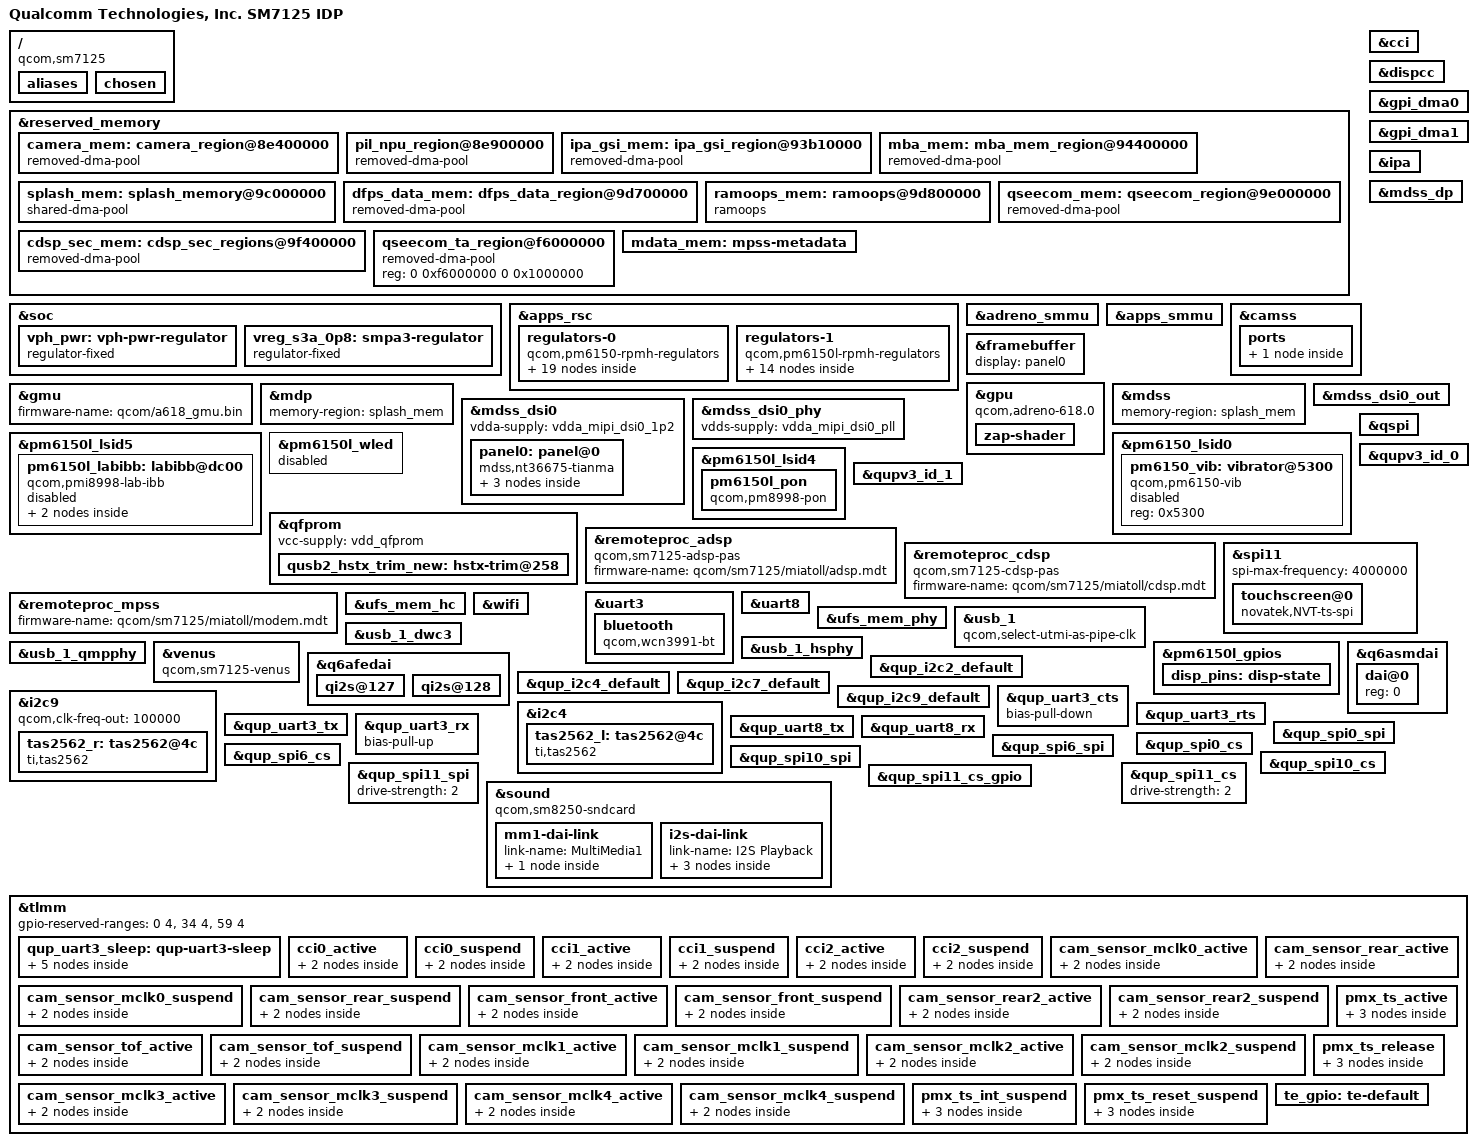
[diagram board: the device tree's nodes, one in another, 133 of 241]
// SPDX-License-Identifier: BSD-3-Clause
/*
 * SM7125 IDP board device tree source
 *
 * Copyright (c) 2019, The Linux Foundation. All rights reserved.
 * Copyright (c) 2023, 99degree <https://github.com/99degree/>
 *
 */

/dts-v1/;

#include <dt-bindings/arm/qcom,ids.h>
#include <dt-bindings/firmware/qcom,scm.h>
#include <dt-bindings/gpio/gpio.h>
#include <dt-bindings/regulator/qcom,rpmh-regulator.h>
#include <dt-bindings/pinctrl/qcom,pmic-gpio.h>
#include <dt-bindings/sound/qcom,q6asm.h>
#include "sm7125-xiaomi-common.dtsi"
#include "sm7125-idp.dtsi"
#include "pm6150.dtsi"
#include "pm6150l.dtsi"

/delete-node/ &cont_splash_mem;

/ {
	model = "Qualcomm Technologies, Inc. SM7125 IDP";
	compatible = "qcom,sm7125", "qcom,sc7180-idp", "qcom,sc7180";
	qcom,board-id = <0x50022 0x1>;
	qcom,msm-name = "ATOLL-AB";
	qcom,pmic-name = "PM6150";

	aliases {
		bluetooth0 = &bluetooth;
		hsuart0 = &uart3;
		serial0 = &uart8;
		wifi0 = &wifi;
		qupv3_se9_i2c = &i2c9;
		qupv3_se4_i2c = &i2c4;

	};

	chosen {
		#address-cells = <2>;
		#size-cells = <2>;
		ranges;

		//TODO: remove unneeded once all sorta out.
		bootargs = "pd_ignore_unused no_console_suspend kpti=off nokaslr ignore_loglevel clk_ignore_unused";

		stdout-path = "serial0:115200n8";
	};

};


/*
 * Reserved memory changes
 *
 * Delete all unused memory nodes and define the peripheral memory regions
 * required by the board dts.
 *
 */

&reserved_memory {
	
/*
[    0.000000] Memory limit set/overridden to 5068MB
[    0.000000] Reserved memory: created CMA memory pool at 0x00000000f7000000, size 140 MiB
[    0.000000] OF: reserved mem: initialized node secure_display_region, compatible id shared-dma-pool
[    0.000000] Reserved memory: created CMA memory pool at 0x00000000f6000000, size 16 MiB
[    0.000000] OF: reserved mem: initialized node qseecom_ta_region, compatible id shared-dma-pool
[    0.000000] Reserved memory: created CMA memory pool at 0x00000000f5800000, size 8 MiB
[    0.000000] OF: reserved mem: initialized node adsp_region, compatible id shared-dma-pool
[    0.000000] Reserved memory: created CMA memory pool at 0x00000000f3800000, size 32 MiB
[    0.000000] OF: reserved mem: initialized node linux,cma, compatible id shared-dma-pool

[    0.000000] Removed memory: created DMA memory pool at 0x0000000080000000, size 6 MiB
[    0.000000] OF: reserved mem: initialized node hyp_region@80000000, compatible id removed-dma-pool
[    0.000000] Removed memory: created DMA memory pool at 0x0000000080700000, size 1 MiB
[    0.000000] OF: reserved mem: initialized node xbl_aop_mem@80700000, compatible id removed-dma-pool
[    0.000000] Removed memory: created DMA memory pool at 0x00000000808ff000, size 0 MiB
[    0.000000] OF: reserved mem: initialized node sec_apps_region@808ff000, compatible id removed-dma-pool
[    0.000000] Removed memory: created DMA memory pool at 0x0000000080900000, size 2 MiB
[    0.000000] OF: reserved mem: initialized node smem@80900000, compatible id removed-dma-pool
[    0.000000] Removed memory: created DMA memory pool at 0x0000000080b00000, size 57 MiB
[    0.000000] OF: reserved mem: initialized node removed_region@80b00000, compatible id removed-dma-pool
[    0.000000] Removed memory: created DMA memory pool at 0x0000000086000000, size 132 MiB
[    0.000000] OF: reserved mem: initialized node modem_region@86000000, compatible id removed-dma-pool
[    0.000000] Removed memory: created DMA memory pool at 0x000000008e400000, size 5 MiB
[    0.000000] OF: reserved mem: initialized node camera_region@8e400000, compatible id removed-dma-pool
[    0.000000] Removed memory: created DMA memory pool at 0x000000008e900000, size 5 MiB
[    0.000000] OF: reserved mem: initialized node pil_npu_region@8e900000, compatible id removed-dma-pool
[    0.000000] Removed memory: created DMA memory pool at 0x000000008ee00000, size 5 MiB
[    0.000000] OF: reserved mem: initialized node pil_video_region@8ee00000, compatible id removed-dma-pool
[    0.000000] Removed memory: created DMA memory pool at 0x000000008f300000, size 30 MiB
[    0.000000] OF: reserved mem: initialized node cdsp_regions@8f300000, compatible id removed-dma-pool
[    0.000000] Removed memory: created DMA memory pool at 0x0000000091100000, size 40 MiB
[    0.000000] OF: reserved mem: initialized node pil_adsp_region@91100000, compatible id removed-dma-pool
[    0.000000] Removed memory: created DMA memory pool at 0x0000000093900000, size 2 MiB
[    0.000000] OF: reserved mem: initialized node wlan_fw_region@93900000, compatible id removed-dma-pool
[    0.000000] Removed memory: created DMA memory pool at 0x0000000093b00000, size 0 MiB
[    0.000000] OF: reserved mem: initialized node ipa_fw_region@93b00000, compatible id removed-dma-pool
[    0.000000] Removed memory: created DMA memory pool at 0x0000000093b10000, size 0 MiB
[    0.000000] OF: reserved mem: initialized node ipa_gsi_region@93b10000, compatible id removed-dma-pool
[    0.000000] Removed memory: created DMA memory pool at 0x0000000093b15000, size 0 MiB
[    0.000000] OF: reserved mem: initialized node gpu_region@93b15000, compatible id removed-dma-pool
[    0.000000] Reserved memory: created DMA memory pool at 0x000000009e000000, size 20 MiB
[    0.000000] OF: reserved mem: initialized node qseecom_region@9e000000, compatible id shared-dma-pool
[    0.000000] Removed memory: created DMA memory pool at 0x000000009f400000, size 30 MiB
[    0.000000] OF: reserved mem: initialized node cdsp_sec_regions@0x9f400000, compatible id removed-dma-pool
[    0.000000] cma: dma_contiguous_reserve(limit 100000000)
*/	

#if 0
		/* below node will get modified by bootloader, node name can't change. */
		kernel_mem: memory@80000000 {
			compatible = "removed-dma-pool";
			no-map;
			reg = <0x00 0x80000000 0x00 0x600000>;
		};
		
		memory@80600000 {
			compatible = "removed-dma-pool";
			no-map;
			reg = <0x00 0x80600000 0x00 0x200000>;
		};

		memory@808ff000 {
			compatible = "removed-dma-pool";
			no-map;
			reg = <0x00 0x808ff000 0x00 0x1000>;
		};

		smem: memory@80900000 {
			compatible = "removed-dma-pool";
			no-map;
			reg = <0x00 0x80900000 0x00 0x200000>;
		};

		atf_mem: memory@80b00000 {
			compatible = "removed-dma-pool";
			no-map;
			reg = <0x00 0x80b00000 0x00 0x3900000>;
		};
#endif
		camera_mem: camera_region@8e400000 {
			compatible = "removed-dma-pool";
			no-map;
			reg = <0x00 0x8e400000 0x00 0x500000>;
		};
		
		pil_npu_region@8e900000 {
			compatible = "removed-dma-pool";
			no-map;
			reg = <0x00 0x8e900000 0x00 0x500000>;
		};

		ipa_gsi_mem: ipa_gsi_region@93b10000 {
			compatible = "removed-dma-pool";
			no-map;
			reg = <0x00 0x93b10000 0x00 0x5000>;
		};

		mba_mem: mba_mem_region@94400000 {
			compatible = "removed-dma-pool";
			reg = <0x0 0x94400000 0x0 0x200000>;
			no-map;
		};

		splash_mem: splash_memory@9c000000 {
			compatible = "shared-dma-pool";
			reg = <0x0 0x9c000000 0x0 0x1700000>;
			no-map;
		};

		dfps_data_mem: dfps_data_region@9d700000 {
			reg = <0x00 0x9d700000 0x00 0x100000>;
			compatible = "removed-dma-pool";
			no-map;
		};
		
		ramoops_mem: ramoops@9d800000 {
			compatible = "ramoops", "removed-dma-pool";
			reg = <0x00 0x9d800000 0x00 0x600000>;
			console-size = <0x100000>;
			ftrace-size = <0x200000>;			
			ecc-size = <0x10>;
			pmsg-size = <0x200000>;
			record-size = <0x80000>;
		};

		qseecom_mem: qseecom_region@9e000000 {
			compatible = "removed-dma-pool";
			no-map;
			reg = <0x00 0x9e000000 0x00 0x1400000>;
		};
		
		cdsp_sec_mem: cdsp_sec_regions@9f400000 {
			compatible = "removed-dma-pool";
			no-map;
			reg = <0x00 0x9f400000 0x00 0x1e00000>;
		};

#if 0
		linux,cma@f3800000 {
			compatible = "shared-dma-pool";
			reg = <0 0xf3800000 0 0x2000000>;
		};
#endif
		qseecom_ta_region@f6000000 {
			compatible = "removed-dma-pool";
			reg = <0 0xf6000000 0 0x1000000>;
		};
		
#if 0
		secure_display_region@f7000000 {
			compatible = "shared-dma-pool";
			reg = <0 0xf7000000 0 0x8c00000>;
			
		};
#endif
		mdata_mem: mpss-metadata {
			alloc-ranges = <0x0 0xa0000000 0x0 0x20000000>;
			size = <0x0 0x4000>;
			no-map;
		};
};

&soc {
	vph_pwr: vph-pwr-regulator {
		compatible = "regulator-fixed";
		regulator-name = "vph_pwr";
		regulator-min-microvolt = <3700000>;
		regulator-max-microvolt = <3700000>;
	};

	// S3A is really mx.lvl but it's there for supply map completeness sake.
	vreg_s3a_0p8: smpa3-regulator {
		compatible = "regulator-fixed";
		regulator-name = "vreg_s3a_0p8";

		regulator-min-microvolt = <800000>;
		regulator-max-microvolt = <800000>;
		regulator-always-on;
		vin-supply = <&vph_pwr>;
	};
};

&apps_rsc {
	regulators-0 {
		compatible = "qcom,pm6150-rpmh-regulators";
		qcom,pmic-id = "a";

		vdd-s1-supply = <&vph_pwr>;
		vdd-s2-supply = <&vph_pwr>;
		vdd-s3-supply = <&vph_pwr>;
		vdd-s4-supply = <&vph_pwr>;
		vdd-s5-supply = <&vph_pwr>;

		vdd-l1-supply = <&vreg_s8c_1p35>;
		vdd-l2-l3-supply = <&vreg_s4a_1p1>;
		vdd-l4-l7-l8-supply = <&vreg_s4a_1p1>;
		vdd-l5-l16-l17-l18-l19-supply = <&vreg_bob>;
		vdd-l6-supply = <&vreg_s8c_1p35>;
		vdd-l9-supply = <&vreg_s3a_0p8>;
		vdd-l10-l14-l15-supply = <&vreg_s5a_2p0>;
		vdd-l11-l12-l13-supply = <&vreg_s5a_2p0>;

		/*
		 * S1 are unused.
		 * S2-S3, L7-L8 are ARCs:
		 * S2 - gfx.lvl,
		 * S3 - mx.lvl,
		 * L7 - lmx.lvl,
		 * L8 - lcx.lvl.
		 */

		vreg_s4a_1p1: smps4 {
			regulator-min-microvolt = <824000>;
			regulator-max-microvolt = <1120000>;
		};

		vreg_s5a_2p0: smps5 {
			regulator-min-microvolt = <1744000>;
			regulator-max-microvolt = <2040000>;
		};

		vreg_l1a_1p2: ldo1 {
			//regulator-min-microvolt = <1096000>;
			//regulator-max-microvolt = <1304000>;
			regulator-min-microvolt = <1178000>;
			regulator-max-microvolt = <1256000>;
			regulator-initial-mode = <RPMH_REGULATOR_MODE_HPM>;
		};

		vreg_l2a_1p0: ldo2 {
			regulator-min-microvolt = <944000>;
			regulator-max-microvolt = <1056000>;
			regulator-initial-mode = <RPMH_REGULATOR_MODE_HPM>;
		};

		vdda_pll_cc_ebi01:
		vreg_l3a_1p0: ldo3 {
			regulator-min-microvolt = <968000>;
			regulator-max-microvolt = <1064000>;
			regulator-initial-mode = <RPMH_REGULATOR_MODE_HPM>;
		};

		vdd_qlink_lv:
		vdd_qlink_lv_ck:
		vdd_usb_hs_core:
		vdda_mipi_csi0_0p9:
		vdda_mipi_csi1_0p9:
		vdda_mipi_csi2_0p9:
		vdda_mipi_csi3_0p9:
		vdda_mipi_dsi0_pll:
		vdda_mipi_dsi1_pll:
		vdda_qrefs_0p9:
		vdda_ufs_core:
		vdda_usb_ss_dp_core:
		vreg_l4a_0p88: ldo4 {
			regulator-min-microvolt = <824000>;
			/* from downstream 824000 - 924000 */
			regulator-max-microvolt = <924000>;
			regulator-initial-mode = <RPMH_REGULATOR_MODE_HPM>;
		};

		vreg_l5a_2p7: ldo5 {
			/* from downstream 2496000 - 3000000 */
			regulator-min-microvolt = <2600000>;
			regulator-max-microvolt = <2800000>;
			regulator-initial-mode = <RPMH_REGULATOR_MODE_HPM>;
		};

		vreg_l6a_1p2: ldo6 {
			//regulator-min-microvolt = <1096000>;
			//regulator-max-microvolt = <1304000>;
			regulator-min-microvolt = <568000>;
			regulator-max-microvolt = <648000>;			
			regulator-initial-mode = <RPMH_REGULATOR_MODE_HPM>;
		};

		vdd_wcss_cx:
		vreg_l9a_0p8: ldo9 {
			//regulator-min-microvolt = <624000>;
			//regulator-max-microvolt = <760000>;
			/* downstream 488000 - 800000 and thighten to 624000 - 800000 */
			regulator-min-microvolt = <624000>;
			regulator-max-microvolt = <800000>;
			regulator-initial-mode = <RPMH_REGULATOR_MODE_HPM>;
		};

		vddpx_3:
		vreg_l10a_1p8: ldo10 {
			/* downstream 1800000 - 1832000 */
			//regulator-min-microvolt = <1720000>;
			regulator-min-microvolt = <1800000>;
			regulator-max-microvolt = <1832000>;
			regulator-initial-mode = <RPMH_REGULATOR_MODE_HPM>;
		};

		vdd_qfprom:
		vdda_apc1_cs_1p8:
		vdda_qrefs_1p8:
		vdda_usb_hs_1p8:
		vddpx_11:
		vreg_l11a_1p8: ldo11 {
			regulator-min-microvolt = <1696000>;
			//regulator-max-microvolt = <1984000>;
			regulator-max-microvolt = <1904000>;
			regulator-initial-mode = <RPMH_REGULATOR_MODE_HPM>;
		};

		vreg_l12a_1p8: ldo12 {
			regulator-min-microvolt = <1696000>;
			regulator-max-microvolt = <1952000>;
			regulator-initial-mode = <RPMH_REGULATOR_MODE_HPM>;
		};

		vreg_l13a_1p8: ldo13 {
			regulator-min-microvolt = <1696000>;
			regulator-max-microvolt = <1904000>;
			regulator-initial-mode = <RPMH_REGULATOR_MODE_HPM>;
		};

		vreg_l14a_1p8: ldo14 {
			regulator-min-microvolt = <1720000>;
			//regulator-max-microvolt = <1856000>;
			regulator-max-microvolt = <1832000>;
			regulator-initial-mode = <RPMH_REGULATOR_MODE_HPM>;
		};

		vreg_l15a_1p8: ldo15 {
			regulator-min-microvolt = <1696000>;
			regulator-max-microvolt = <1904000>;
			regulator-initial-mode = <RPMH_REGULATOR_MODE_HPM>;
		};

		vreg_l16a_2p8: ldo16 {
			/* As the label well-said... */
			//regulator-min-microvolt = <1800000>;
			//regulator-max-microvolt = <1800000>;
			regulator-min-microvolt = <2496000>;
			regulator-max-microvolt = <3304000>;
			regulator-initial-mode = <RPMH_REGULATOR_MODE_HPM>;
		};

		vdda_usb_hs_3p1:
		vreg_l17a_3p1: ldo17 {
			/* downstream 2920000 - 3232000 */
			//regulator-min-microvolt = <3000000>;
			regulator-min-microvolt = <2920000>;
			regulator-max-microvolt = <3232000>;
			regulator-initial-mode = <RPMH_REGULATOR_MODE_HPM>;
		};

		/* 
		 * downstream display-sde.dtsi noded ad vdd3p3 it is resonable 
		 * to set as 3p0. and the dtb dump might wrong caused LCD panel
		 * refresh gonna wrong murra in 60Hz and the issue gone when set to 30Hz.
		 * but cant set as high due to above suspect.
		*/
		vreg_l18a_2p8: ldo18 {
			//regulator-min-microvolt = <3000000>;
			//regulator-max-microvolt = <3000000>;
			regulator-min-microvolt = <1696000>;
			regulator-max-microvolt = <1904000>;
			regulator-initial-mode = <RPMH_REGULATOR_MODE_HPM>;
		};

		vreg_l19a_2p85: ldo19 {
			/* downstream 2696000 - 3304000 */			
			regulator-min-microvolt = <2944000>;
			regulator-max-microvolt = <3304000>;
			regulator-initial-mode = <RPMH_REGULATOR_MODE_HPM>;
		};
	};

	regulators-1 {
		compatible = "qcom,pm6150l-rpmh-regulators";
		qcom,pmic-id = "c";

		vdd-s1-supply = <&vph_pwr>;
		vdd-s2-supply = <&vph_pwr>;
		vdd-s3-supply = <&vph_pwr>;
		vdd-s4-supply = <&vph_pwr>;
		vdd-s5-supply = <&vph_pwr>;
		vdd-s6-supply = <&vph_pwr>;
		vdd-s7-supply = <&vph_pwr>;
		vdd-s8-supply = <&vph_pwr>;

		/*
		 * There should be:
		 * vdd-l1-l8-supply = <&vreg_s5a_2p0>;
		 * But pm7150l doesn't have access to S5A.
		 */

		vdd-l2-l3-supply = <&vreg_s8c_1p35>;
		vdd-l4-l5-l6-supply = <&vreg_bob>;
#if 0
		/* disabled due to usb fail at miatoll boot */
		vdd-l7-l11-supply = <&vreg_bob>;
#endif
		vdd-l9-l10-supply = <&vreg_bob>;

		vdd-bob-supply = <&vph_pwr>;
		vdd-flash-supply = <&vreg_bob>;
		vdd-rgb-supply = <&vreg_bob>;

		/*
		 * S4, S5 are unused.
		 * S2, S3, S7 are ARCs:
		 * S2-S3 - cx.lvl,
		 * S7 - mss.lvl.
		 */

		vreg_s1c_1p13: smps1 {
			regulator-min-microvolt = <1000000>;
			regulator-max-microvolt = <1200000>;
		};

		vreg_s8c_1p35: smps8 {
			regulator-min-microvolt = <1120000>;
			regulator-max-microvolt = <1408000>;
		};

		vreg_l1c_1p8: ldo1 {
			regulator-min-microvolt = <1616000>;
			regulator-max-microvolt = <1984000>;
			regulator-initial-mode = <RPMH_REGULATOR_MODE_HPM>;
		};

		vdd_wcss_adc_dac:
		vreg_l2c_1p3: ldo2 {
			//regulator-min-microvolt = <1200000>;
			//regulator-max-microvolt = <1352000>;
			regulator-min-microvolt = <1168000>;
			regulator-max-microvolt = <1304000>;
			regulator-initial-mode = <RPMH_REGULATOR_MODE_HPM>;
		};

		vdda_csi0_1p25:
		vdda_csi1_1p25:
		vdda_csi2_1p25:
		vdda_csi3_1p25:
		vdda_hv_ebi0:
		vdda_mipi_dsi0_1p2:
		vdda_mipi_dsi1_1p2:
		vdda_ufs_1p2:
		vdda_usb_ss_dp_1p2:
		vddpx_10:
		vreg_l3c_1p23: ldo3 {
			/* downstream 1144000 - 1304000 */
			regulator-min-microvolt = <1144000>;
			//regulator-max-microvolt = <1256000>;
			regulator-max-microvolt = <1304000>;
			regulator-initial-mode = <RPMH_REGULATOR_MODE_HPM>;
		};

		vddpx_5:
		vreg_l4c_1p8: ldo4 {
			/* downstream 1648000 - 3304000 */
			regulator-min-microvolt = <1648000>;
			//regulator-max-microvolt = <2950000>;
			regulator-max-microvolt = <3304000>;
			regulator-initial-mode = <RPMH_REGULATOR_MODE_HPM>;
		};

		vddpx_6:
		vreg_l5c_1p8: ldo5 {
			regulator-min-microvolt = <1648000>;
			/* downstream 1648000 - 3304000 */
			//regulator-max-microvolt = <2950000>;
			regulator-max-microvolt = <3304000>;
			regulator-initial-mode = <RPMH_REGULATOR_MODE_HPM>;
		};

		vddpx_2:
		vreg_l6c_3p0: ldo6 {
			regulator-min-microvolt = <1648000>;
			/* downstream 1648000 - 3304000 */
			//regulator-max-microvolt = <3100000>;
			regulator-max-microvolt = <3304000>;
			regulator-initial-mode = <RPMH_REGULATOR_MODE_HPM>;
			regulator-allow-set-load;
			regulator-allowed-modes = <RPMH_REGULATOR_MODE_LPM
						   RPMH_REGULATOR_MODE_HPM>;
		};

		vreg_l7c_3p0: ldo7 {
			regulator-min-microvolt = <3000000>;
			regulator-max-microvolt = <3312000>;
			regulator-initial-mode = <RPMH_REGULATOR_MODE_HPM>;
			regulator-always-on;
		};

		vreg_l8c_1p8: ldo8 {
			/* downstream 1800000 - 1904000 */
			regulator-min-microvolt = <1800000>;
			regulator-max-microvolt = <1900000>;
			regulator-initial-mode = <RPMH_REGULATOR_MODE_HPM>;
		};

		/*
		 * Downstream specifies a range of 2950-3312mV.
		 * Tighten the range to 2950-3100mV.
		 */
		vreg_l9c_3p1: ldo9 {
			regulator-min-microvolt = <2950000>;
			regulator-max-microvolt = <3100000>;
			regulator-initial-mode = <RPMH_REGULATOR_MODE_HPM>;
			regulator-allow-set-load;
			regulator-allowed-modes = <RPMH_REGULATOR_MODE_LPM
						   RPMH_REGULATOR_MODE_HPM>;
		};

		vreg_l10c_3p3: ldo10 {
			/* downstream 3000000 - 3400000 */
			regulator-min-microvolt = <3200000>;
			//regulator-max-microvolt = <3312000>;
			regulator-max-microvolt = <3400000>;
			regulator-initial-mode = <RPMH_REGULATOR_MODE_HPM>;
		};

		vreg_l11c_3p3: ldo11 {
			//regulator-min-microvolt = <2950000>;
			regulator-min-microvolt = <3000000>;
			regulator-max-microvolt = <3400000>;
			regulator-initial-mode = <RPMH_REGULATOR_MODE_HPM>;
		};

		vreg_bob: bob {
			regulator-min-microvolt = <3296000>;
			regulator-max-microvolt = <3960000>;
			regulator-initial-mode = <RPMH_REGULATOR_MODE_AUTO>;
			regulator-allow-bypass;
		};
	};
};

&adreno_smmu {
        status = "okay";
};

&apps_smmu {
        status = "okay";
};

&camss {
	//vdda-phy-supply = <&vreg_l1a_0p875>;
	//vdda-pll-supply = <&vreg_l26a_1p2>;

	status = "okay";

	ports {
		port@0 {
#if 0
			csiphy0_ep: endpoint {
				data-lanes = <0 1 2 3>;
				//remote-endpoint = <&ov8856_ep>;
			};
#endif
		};
	};
};

&cci {
        status = "okay";
};

&dispcc {
	status = "okay";
};

&framebuffer {
        display = <&panel0>;
        status = "okay";
};

&gpu {
	compatible = "qcom,adreno-618.0", "qcom,adreno";
	firmware-name = "qcom/sm7125/miatoll/a615_zap.mbn";

	status = "okay";

	zap-shader {
			memory-region = <&gpu_mem>;
			firmware-name = "qcom/sm7125/miatoll/a615_zap.mbn";
	};
};

&gmu {
	firmware-name = "qcom/a618_gmu.bin";
	status = "okay";
};

&gpi_dma0 {
	status = "okay";
};

&gpi_dma1 {
	status = "okay";
};

&ipa {
	memory-region = <&ipa_fw_mem>;
	firmware-name = "qcom/sm7125/miatoll/ipa_fws.mbn";

	status = "okay";
};

&mdp {
	// TODO: check if mdss or mdp hold this memory
	memory-region = <&splash_mem>;

	status = "okay";
};

&mdss {
	// TODO: check if mdss or mdp hold this memory
	memory-region = <&splash_mem>;
	status = "okay";
};

&mdss_dp {
        status = "okay";
};

&mdss_dsi0 {
	vdda-supply = <&vdda_mipi_dsi0_1p2>;
	status = "okay";

	panel0: panel@0 {
	};
};

&mdss_dsi0_out {
	remote-endpoint = <&panel0_in>;
	data-lanes = <0 1 2 3>;

	status = "okay";
};

&mdss_dsi0_phy {
	vdds-supply = <&vdda_mipi_dsi0_pll>;

	status = "okay";
};

&panel0 {
	compatible = "mdss,nt36675-tianma", 
			"mdss,nt36675-tianma-fhd";

	reg = <0>;
	
	/* TODO: check vreg l3c/l3a */
	//vdda-supply = <&vreg_l3c_1p23>; //from downstream, need to double check
	//vdd3p3-supply = <&vreg_l18a_2p8>;
	//vddio-supply = <&vreg_l13a_1p8>; //from sm7150-xiaomi-common.dtsi
	vddio-supply = <&vreg_l18a_2p8>;

#if 0
	/* 
		display_sde.dtsi
			vddio-supply = <&L13A>;
			vdda-3p3-supply = <&L18A>;
		---
		cust-atoll-sde-display.dtsi
			/delete-property/ vdda-3p3-supply;

		        vddio-supply = <&L18A>;
	*/

	lab-supply = <&lab>;
	ibb-supply = <&ibb>;
#endif
	//backlight = <&pm6150l_wled>;

	pinctrl-names = "default", "te_pin"; //TODO: need to figure out how to handle te_pin
	pinctrl-0 = <&disp_pins>;
        pinctrl-1 = <&te_gpio>;

	/* according to panel-nt36675-tianma.c this gpio is finally set to low */
	reset-gpios = <&pm6150l_gpios 3 GPIO_ACTIVE_LOW>;
	//disp-te-gpio = <&tlmm 10 GPIO_ACTIVE_LOW>;

	status = "okay";

	ports {
		#address-cells = <1>;
		#size-cells = <0>;
		port@0 {
			reg = <0>;
			panel0_in: endpoint {
				remote-endpoint = <&mdss_dsi0_out>;
			};
		};
	};
};
	
&pm6150l_lsid5 {
	pm6150l_labibb: labibb@dc00 {
		compatible = "qcom,pmi8998-lab-ibb";
		
		status = "disabled";

		ibb: ibb@dc00 {
			interrupts = <0x5 0xdc 0x2 IRQ_TYPE_EDGE_RISING>,
						 <0x5 0xdc 0x0 IRQ_TYPE_LEVEL_HIGH>;
			interrupt-names = "sc-err", "ocp";

			regulator-min-microvolt = <4600000>;
			regulator-max-microvolt = <6000000>;
			regulator-over-current-protection;
			regulator-pull-down;
			regulator-soft-start;
			qcom,discharge-resistor-kohms = <300>;
		};

		lab: lab@de00 {
			interrupts = <0x5 0xde 0x1 IRQ_TYPE_EDGE_RISING>,
						 <0x5 0xde 0x0 IRQ_TYPE_LEVEL_LOW>;
			interrupt-names = "sc-err", "ocp";

			regulator-min-microvolt = <4600000>;
			regulator-max-microvolt = <6000000>;
			regulator-over-current-protection;
			regulator-pull-down;
			regulator-soft-start;
		};
	};
};

/* dont wanna change pm6150.dtsi for merge difficulty */
&pm6150_lsid0 {
		pm6150_vib: vibrator@5300 {
			compatible = "qcom,pm6150-vib", "qcom,pmi632-vib";
			reg = <0x5300>;
			status = "disabled";
		};
};

&pm6150l_wled {
	/* ok copy from fair-phone dts */
        qcom,switching-freq = <800>;
        qcom,current-limit-microamp = <20000>;
        qcom,num-strings = <2>;

	status = "okay";
};

&pm6150l_lsid4 {
	pm6150l_pon {
			compatible = "qcom,pm8998-pon";
			reg = <0x800>;
			mode-bootloader = <0x2>;
			mode-recovery = <0x1>;

			mode-shutdown = <0x4>;
			mode-poweroff = <0x4>;
			mode-hardreset = <0x7>;
	};

};

&qfprom {
	vcc-supply = <&vdd_qfprom>;
	status = "okay";
	
	qusb2_hstx_trim_new: hstx-trim@258 {
			reg = <0x258 0x1>;
			bits = <25 3>;
	};
};

&qspi {
	pinctrl-names = "default";
	pinctrl-0 = <&qspi_clk &qspi_cs0 &qspi_data0 &qspi_data1>;
	
	status = "okay";
};

&qupv3_id_0 {
	status = "okay";
};

&qupv3_id_1 {
	status = "okay";
};

&remoteproc_adsp {
	compatible = "qcom,sm7125-adsp-pas", "qcom,sc7280-adsp-pas";
	firmware-name = "qcom/sm7125/miatoll/adsp.mdt";

	status = "okay";
};

&remoteproc_cdsp {
	compatible = "qcom,sm7125-cdsp-pas", "qcom,sc7280-cdsp-pas";
	firmware-name = "qcom/sm7125/miatoll/cdsp.mdt";

	status = "okay";
};

&remoteproc_mpss {
        firmware-name = "qcom/sm7125/miatoll/modem.mdt";
		
        status = "okay";
};

&spi11 {
	spi-max-frequency = <4000000>;
	status = "okay";

	//nt36xxx_touch: i2c@
	touchscreen@0 {
		compatible = "novatek,NVT-ts-spi", "novatek,NVT-ts-spi", "novatek,nt36675-spi";
		reg = <0>;

		spi-max-frequency = <4000000>;

		//interrupts = <&tlmm 41 IRQ_TYPE_EDGE_FALLING>;

		novatek,reset-gpio = <&tlmm 8 0x00>;
		novatek,irq-gpio = <&tlmm 9 0x2001>;

		/* 672C */
		novatek,swrst-n8-addr = <0x03F0FE>;
		novatek,spi-rd-fast-addr = <0x03F310>;

		reset-gpio = <&tlmm 8 0x00>;
		irq-gpio = <&tlmm 9 0x2001>;

		panel = <&panel0>;

		status = "okay";
	};
};

&uart3 {
	/delete-property/interrupts;
	interrupts-extended = <&intc GIC_SPI 604 IRQ_TYPE_LEVEL_HIGH>,
				<&tlmm 41 IRQ_TYPE_EDGE_FALLING>;

	pinctrl-names = "default", "sleep";
	pinctrl-1 = <&qup_uart3_sleep>;
	status = "okay";
	
	bluetooth: bluetooth {
		compatible = "qcom,wcn3991-bt";

		//TODO: add firmware support here
		//firmware-name = "qcom/sm7125/crnv21.bin";

		vddio-supply = <&vreg_l10a_1p8>;
		vddxo-supply = <&vreg_l1c_1p8>;
		vddrf-supply = <&vdd_wcss_adc_dac>;
		vddch0-supply = <&vreg_l10c_3p3>;
		max-speed = <3200000>;
		status = "okay";
	};
};

&uart8 {
	status = "okay";
};

&ufs_mem_hc {
	vcc-supply = <&vreg_l19a_2p85>;
	vcc-max-microamp = <600000>;
	vccq2-supply = <&vreg_l12a_1p8>;
	vccq2-max-microamp = <600000>;

	status = "okay";
};

&ufs_mem_phy {
	vdda-phy-supply = <&vdda_ufs_core>;
	vdda-pll-supply = <&vdda_ufs_1p2>;
	vdda-phy-max-microamp = <62900>;
	vdda-pll-max-microamp = <18300>;

	status = "okay";
};


&usb_1 {
	/* brough from sm6375.dtsi */
	qcom,select-utmi-as-pipe-clk;
	status = "okay";
};

&usb_1_dwc3 {
        dr_mode = "peripheral";
	maximum-speed = "high-speed";
	snps,dis_u2_susphy_quirk;
	snps,dis_enblslpm_quirk;
	snps,has-lpm-erratum;
	snps,hird-threshold = /bits/ 8 <0x10>;
	snps,usb3_lpm_capable;
	tx-fifo-resize;

        status = "okay";
};

/* reassign nvmem cell */
&usb_1_hsphy {
	nvmem-cells = <&qusb2_hstx_trim_new>;

	vdd-supply = <&vdd_usb_hs_core>;
	vdda-pll-supply = <&vdda_usb_hs_1p8>;
	vdda-phy-dpdm-supply = <&vdda_usb_hs_3p1>;

        status = "okay";
};

&usb_1_qmpphy {
	status = "okay";
	vdda-phy-supply = <&vreg_l3c_1p23>;
	vdda-pll-supply = <&vreg_l4a_0p88>;
};

&venus {
	compatible = "qcom,sm7125-venus", "qcom,sc7180-venus";
	memory-region = <&venus_mem>;

	firmware-name = "qcom/sm7125/miatoll/venus.mbn";

	status = "okay";
#if 0
	video-firmware {
		iommus = <&apps_smmu 0x0c42 0x0>;
		firmware-name = "qcom/sm7125/miatoll/venus.mbn";
	};
#endif
};

&wifi {
	vdd-0.8-cx-mx-supply = <&vreg_l9a_0p8>;
	vdd-1.8-xo-supply = <&vreg_l1c_1p8>;
	vdd-1.3-rfa-supply = <&vreg_l2c_1p3>;
	vdd-3.3-ch0-supply = <&vreg_l10c_3p3>;
	vdd-3.3-ch1-supply = <&vreg_l11c_3p3>;

        status = "okay";
/*
	wifi-firmware {
		iommus = <&apps_smmu 0xc2 0x1>;
	};
*/
};

/* PINCTRL - additions to nodes defined in sc7180.dtsi */
&pm6150l_gpios {
	disp_pins: disp-state {
		pins = "gpio3";
		function = PMIC_GPIO_FUNC_FUNC1;
		qcom,drive-strength = <PMIC_GPIO_STRENGTH_MED>;
		power-source = <0>;
		bias-disable;
		output-low;
	};

};

&q6afedai {
        qi2s@127 {
                reg = <QUINARY_MI2S_RX>;
                qcom,sd-lines = <0>;
        };

        qi2s@128 {
                reg = <QUINARY_MI2S_TX>;
                qcom,sd-lines = <1>;
        };
};

&q6asmdai {
        dai@0 {
                reg = <0>;
        };
};

#if 0
&qspi_clk {
	pins = "gpio63";
	bias-disable;
};

&qspi_cs0 {
	pins = "gpio68";
	bias-disable;
};

&qspi_data0 {
	/* High-Z when no transfers; nice to park the lines */
	bias-pull-up;
};

&qspi_data1 {
        /* High-Z when no transfers; nice to park the lines */
        bias-pull-up;
};
#endif

&qup_i2c2_default {
	pins = "gpio15", "gpio16";
	drive-strength = <2>;

	/* Has external pullup */
	bias-disable;
};

&qup_i2c4_default {
	pins = "gpio115", "gpio116";
	drive-strength = <2>;

	/* Has external pullup */
	bias-disable;
};

&qup_i2c7_default {
	pins = "gpio6", "gpio7";
	drive-strength = <2>;

	/* Has external pullup */
	bias-disable;
};

&qup_i2c9_default {
	pins = "gpio46", "gpio47";
	drive-strength = <2>;

	/* Has external pullup */
	bias-disable;
};

&i2c9 {
        status = "ok";

        qcom,clk-freq-out = <100000>;

        tas2562_r: tas2562@4c {
                #sound-dai-cells = <0>;
                compatible = "ti,tas2562";
                reg = <0x4c>;
                ti,left-channel = <0x4c>; /* addr */
                ti,channels = <1>; /* channel number */
                ti,asi-format = <0>; /* 0, i2S; 1, DSP;  */
                ti,reset-gpio = <&tlmm 51 0>;
                ti,irq-gpio = <&tlmm 33 0>;
                ti,left-slot = <0>; /* <left slot number> */
                ti,right-slot = <1>; /* <right slot number> */
                ti,imon-slot-no = <0>; /* <current sense slot number> */
                ti,vmon-slot-no = <2>; /* <current voltage slot number> */
                status = "ok";
        };
};

&i2c4 {
        status = "ok";

        tas2562_l: tas2562@4c {
                #sound-dai-cells = <0>;
                compatible = "ti,tas2562";
                reg = <0x4c>;
                ti,left-channel = <0x4c>; /* addr */
                ti,channels = <1>; /* channel number */
                ti,asi-format = <0>; /* 0, i2S; 1, DSP;  */
                ti,reset-gpio = <&tlmm 51 0>;
                ti,irq-gpio = <&tlmm 33 0>;
                ti,left-slot = <0>; /* <left slot number> */
                ti,right-slot = <1>; /* <right slot number> */
                ti,imon-slot-no = <0>; /* <current sense slot number> */
                ti,vmon-slot-no = <2>; /* <current voltage slot number> */
                status = "ok";
        };
};

&qup_uart3_cts {
	/*
	 * Configure a pull-down on CTS to match the pull of
	 * the Bluetooth module.
	 */
	bias-pull-down;
};

&qup_uart3_rts {
	/* We'll drive RTS, so no pull */
	drive-strength = <2>;
	bias-disable;
};

&qup_uart3_tx {
	/* We'll drive TX, so no pull */
	drive-strength = <2>;
	bias-disable;
};

&qup_uart3_rx {
	/*
	 * Configure a pull-up on RX. This is needed to avoid
	 * garbage data when the TX pin of the Bluetooth module is
	 * in tri-state (module powered off or not driving the
	 * signal yet).
	 */
	bias-pull-up;
};

&qup_uart8_tx {
	drive-strength = <2>;
	bias-disable;
};

&qup_uart8_rx {
	drive-strength = <2>;
	bias-pull-up;
};

&qup_spi0_spi {
	drive-strength = <2>;
	bias-disable;
};

&qup_spi0_cs {
	drive-strength = <2>;
	bias-disable;
};

&qup_spi6_spi {
	drive-strength = <2>;
	bias-disable;
};

&qup_spi6_cs {
	drive-strength = <2>;
	bias-disable;
};

&qup_spi10_spi {
	drive-strength = <2>;
	bias-disable;
};

&qup_spi10_cs {
	drive-strength = <2>;
	bias-disable;
};

&qup_spi11_spi {
	drive-strength = <2>;
	//bias-disable;
};

&qup_spi11_cs {
	drive-strength = <2>;
	//bias-disable;
};

&qup_spi11_cs_gpio {
	drive-strength = <2>;
	bias-disable;
};

&sound {
        compatible = "qcom,sm8250-sndcard";
        pinctrl-0 = <&i2s2_active>;
        pinctrl-names = "default";
        model = "Miatoll";

        mm1-dai-link {
                link-name = "MultiMedia1";
                cpu {
                        sound-dai = <&q6asmdai MSM_FRONTEND_DAI_MULTIMEDIA1>;
                };
        };

        i2s-dai-link {
                link-name = "I2S Playback";
                cpu {
			/*TODO: tertery */
                        sound-dai = <&q6afedai TERTIARY_MI2S_RX>;
                };

                platform {
                        sound-dai = <&q6routing>;
                };

                codec {
                        sound-dai = <&tas2562_r 0>, <&tas2562_l 0>;
                };
        };
};


&tlmm {
	/* adapt from https://github.com/ungeskriptet/linux/tree/sm7125 */
	gpio-reserved-ranges = <0 4>, <34 4>, <59 4>;
	qup_uart3_sleep: qup-uart3-sleep {
		pinmux {
			pins = "gpio38", "gpio39",
			       "gpio40", "gpio41";
			function = "gpio";
		};

		pinconf-cts {
			/*
			 * Configure a pull-down on CTS to match the pull of
			 * the Bluetooth module.
			 */
			pins = "gpio38";
			bias-pull-down;
		};

		pinconf-rts {
			/*
			 * Configure pull-down on RTS. As RTS is active low
			 * signal, pull it low to indicate the BT SoC that it
			 * can wakeup the system anytime from suspend state by
			 * pulling RX low (by sending wakeup bytes).
			 */
			 pins = "gpio39";
			 bias-pull-down;
		};

		pinconf-tx {
			/*
			 * Configure pull-up on TX when it isn't actively driven
			 * to prevent BT SoC from receiving garbage during sleep.
			 */
			pins = "gpio40";
			bias-pull-up;
		};

		pinconf-rx {
			/*
			 * Configure a pull-up on RX. This is needed to avoid
			 * garbage data when the TX pin of the Bluetooth module
			 * is floating which may cause spurious wakeups.
			 */
			pins = "gpio41";
			bias-pull-up;
		};
	};

		cci0_active: cci0_active {
			mux {
				/* CLK, DATA */
				pins = "gpio17", "gpio18";
				function = "cci_i2c";
			};

			config {
				pins = "gpio17", "gpio18";
				bias-pull-up; /* PULL UP*/
				drive-strength = <2>; /* 2 MA */
			};
		};

		cci0_suspend: cci0_suspend {
			mux {
				/* CLK, DATA */
				pins = "gpio17", "gpio18";
				function = "cci_i2c";
			};

			config {
				pins = "gpio17", "gpio18";
				bias-pull-down; /* PULL DOWN */
				drive-strength = <2>; /* 2 MA */
			};
		};

		cci1_active: cci1_active {
			mux {
				/* CLK, DATA */
				pins = "gpio19", "gpio20";
				function = "cci_i2c";
			};

			config {
				pins = "gpio19", "gpio20";
				bias-pull-up; /* PULL UP*/
				drive-strength = <2>; /* 2 MA */
			};
		};

		cci1_suspend: cci1_suspend {
			mux {
				/* CLK, DATA */
				pins = "gpio19", "gpio20";
				function = "cci_i2c";
			};

			config {
				pins = "gpio19", "gpio20";
				bias-pull-down; /* PULL DOWN */
				drive-strength = <2>; /* 2 MA */
			};
		};

		cci2_active: cci2_active {
			mux {
				/* CLK, DATA */
				pins = "gpio27", "gpio28";
				function = "cci_i2c";
			};

			config {
				pins = "gpio27", "gpio28";
				bias-pull-up; /* PULL UP*/
				drive-strength = <2>; /* 2 MA */
			};
		};

		cci2_suspend: cci2_suspend {
			mux {
				/* CLK, DATA */
				pins = "gpio27", "gpio28";
				function = "cci_i2c";
			};

			config {
				pins = "gpio27", "gpio28";
				bias-pull-down; /* PULL DOWN */
				drive-strength = <2>; /* 2 MA */
			};
		};

		cam_sensor_mclk0_active: cam_sensor_mclk0_active {
			/* MCLK0 */
			mux {
				pins = "gpio13";
				function = "cam_mclk";
			};

			config {
				pins = "gpio13";
				bias-disable; /* No PULL */
				drive-strength = <2>; /* 2 MA */
			};
		};

		cam_sensor_mclk0_suspend: cam_sensor_mclk0_suspend {
			/* MCLK0 */
			mux {
				pins = "gpio13";
				function = "cam_mclk";
			};

			config {
				pins = "gpio13";
				bias-pull-down; /* PULL DOWN */
				drive-strength = <2>; /* 2 MA */
			};
		};

		cam_sensor_rear_active: cam_sensor_rear_active {
			/* RESET */
			mux {
				pins = "gpio30";
				function = "gpio";
			};

			config {
				pins = "gpio30";
				bias-disable; /* No PULL */
				drive-strength = <2>; /* 2 MA */
			};
		};

		cam_sensor_rear_suspend: cam_sensor_rear_suspend {
			/* RESET */
			mux {
				pins = "gpio30";
				function = "gpio";
			};

			config {
				pins = "gpio30";
				bias-pull-down; /* PULL DOWN */
				drive-strength = <2>; /* 2 MA */
				output-low;
			};
		};

		cam_sensor_front_active: cam_sensor_front_active {
			/* RESET  */
			mux {
				pins = "gpio29";
				function = "gpio";
			};

			config {
				pins = "gpio29";
				bias-disable; /* No PULL */
				drive-strength = <2>; /* 2 MA */
			};
		};

		cam_sensor_front_suspend: cam_sensor_front_suspend {
			/* RESET */
			mux {
				pins = "gpio29";
				function = "gpio";
			};

			config {
				pins = "gpio29";
				bias-pull-down; /* PULL DOWN */
				drive-strength = <2>; /* 2 MA */
				output-low;
			};
		};

		cam_sensor_rear2_active: cam_sensor_rear2_active {
			/* RESET */
			mux {
				pins = "gpio25";
				function = "gpio";
			};

			config {
				pins = "gpio25";
				bias-disable; /* No PULL */
				drive-strength = <2>; /* 2 MA */
			};
		};

		cam_sensor_rear2_suspend: cam_sensor_rear2_suspend {
			/* RESET */
			mux {
				pins = "gpio25";
				function = "gpio";
			};

			config {
				pins = "gpio25";
				bias-pull-down; /* PULL DOWN */
				drive-strength = <2>; /* 2 MA */
				output-low;
			};
		};

		cam_sensor_tof_active: cam_sensor_tof_active {
			/* RESET */
			mux {
				pins = "gpio24";
				function = "gpio";
			};

			config {
				pins = "gpio24";
				bias-disable; /* No PULL */
				drive-strength = <2>; /* 2 MA */
			};
		};

		cam_sensor_tof_suspend: cam_sensor_tof_suspend {
			/* RESET */
			mux {
				pins = "gpio24";
				function = "gpio";
			};

			config {
				pins = "gpio24";
				bias-pull-down; /* PULL DOWN */
				drive-strength = <2>; /* 2 MA */
				output-low;
			};
		};

		cam_sensor_mclk1_active: cam_sensor_mclk1_active {
			/* MCLK1 */
			mux {
				pins = "gpio14";
				function = "cam_mclk";
			};

			config {
				pins = "gpio14";
				bias-disable; /* No PULL */
				drive-strength = <2>; /* 2 MA */
			};
		};

		cam_sensor_mclk1_suspend: cam_sensor_mclk1_suspend {
			/* MCLK1 */
			mux {
				pins = "gpio14";
				function = "cam_mclk";
			};

			config {
				pins = "gpio14";
				bias-pull-down; /* PULL DOWN */
				drive-strength = <2>; /* 2 MA */
			};
		};

		cam_sensor_mclk2_active: cam_sensor_mclk2_active {
			/* MCLK2 */
			mux {
				pins = "gpio15";
				function = "cam_mclk";
			};

			config {
				pins = "gpio15";
				bias-disable; /* No PULL */
				drive-strength = <2>; /* 2 MA */
			};
		};

		cam_sensor_mclk2_suspend: cam_sensor_mclk2_suspend {
			/* MCLK2 */
			mux {
				pins = "gpio15";
				function = "cam_mclk";
			};

			config {
				pins = "gpio15";
				bias-pull-down; /* PULL DOWN */
				drive-strength = <2>; /* 2 MA */
			};
		};

		cam_sensor_mclk3_active: cam_sensor_mclk3_active {
			/* MCLK3 */
			mux {
				pins = "gpio16";
				function = "cam_mclk";
			};

			config {
				pins = "gpio16";
				bias-disable; /* No PULL */
				drive-strength = <2>; /* 2 MA */
			};
		};

		cam_sensor_mclk3_suspend: cam_sensor_mclk3_suspend {
			/* MCLK3 */
			mux {
				pins = "gpio16";
				function = "cam_mclk";
			};

			config {
				pins = "gpio16";
				bias-pull-down; /* PULL DOWN */
				drive-strength = <2>; /* 2 MA */
			};
		};

		cam_sensor_mclk4_active: cam_sensor_mclk4_active {
			/* MCLK4 */
			mux {
				pins = "gpio23";
				function = "cam_mclk";
			};

			config {
				pins = "gpio23";
				bias-disable; /* No PULL */
				drive-strength = <2>; /* 2 MA */
			};
		};

		cam_sensor_mclk4_suspend: cam_sensor_mclk4_suspend {
			/* MCLK4 */
			mux {
				pins = "gpio23";
				function = "cam_mclk";
			};

			config {
				pins = "gpio23";
				bias-pull-down; /* PULL DOWN */
				drive-strength = <2>; /* 2 MA */
			};
		};

        pmx_ts_active {
                ts_active: ts_active {
                                mux {
                                        pins = "gpio8", "gpio9";
                                        function = "gpio";
                                };

                                config {
                                        pins = "gpio8", "gpio9";
                                        drive-strength = <8>;
                                        bias-pull-up;
                                };
                        };
        };

                pmx_ts_int_suspend {
                        ts_int_suspend: ts_int_suspend {
                                mux {
                                        pins = "gpio9";
                                        function = "gpio";
                                };

                                config {
                                        pins = "gpio9";
                                        drive-strength = <2>;
                                        bias-disable;
                                };
                        };
                };

                pmx_ts_reset_suspend {
                        ts_reset_suspend: ts_reset_suspend {
                                mux {
                                        pins = "gpio8";
                                        function = "gpio";
                                };

                                config {
                                        pins = "gpio8";
                                        drive-strength = <2>;
                                        bias-disable;
                                };
                        };
                };

                pmx_ts_release {
                        ts_release: ts_release {
                                mux {
                                        pins = "gpio9", "gpio8";
                                        function = "gpio";
                                };

                                config {
                                        pins = "gpio9", "gpio8";
                                        drive-strength = <2>;
                                        bias-disable;
                                };
                        };
                };

        te_gpio: te-default {
                pins = "gpio10";
                function = "mdp_vsync";
                drive-strength = <2>;   /* 2 mA */
                bias-pull-down;         /* PULL DOWN */
        };
};

/*
	below are one-liner control on/off
*/

#if 0
/* Below are one-liner control status */
&spi0      { status = "disabled"; };
&spi1      { status = "disabled"; };
&spi3      { status = "disabled"; };
&spi5      { status = "disabled"; };
&spi6      { status = "disabled"; };
&spi8      { status = "disabled"; };

&i2c1      { status = "disabled"; };
&i2c2      { status = "disabled"; };
&i2c3      { status = "disabled"; };
&i2c5      { status = "disabled"; };
&i2c6      { status = "disabled"; };
&i2c7      { status = "disabled"; };
&i2c8      { status = "disabled"; };
&i2c10     { status = "disabled"; };
&i2c11     { status = "disabled"; };
#endif

#if 0
&uart0    { status = "disabled" ;};
&uart1    { status = "disabled" ;};
&uart2    { status = "disabled" ;};
&uart3    { status = "disabled" ;}; //enabled default to bt
&uart4    { status = "disabled" ;};
&uart5    { status = "disabled" ;};
&uart6    { status = "disabled" ;};
&uart7    { status = "disabled" ;};
&uart8    { status = "disabled" ;}; //enabled not sure for what
&uart9    { status = "disabled" ;};
&uart10   { status = "disabled" ;};
&uart11   { status = "disabled" ;};
#endif

//&qspi { status = "disabled"; };
//&qupv3_id_0 { status = "disabled"; };
//&qupv3_id_1 { status = "disabled"; };

///{ smp2p-mpss { status = "disabled" ;}; };
///{ smp2p-lpass { status = "disabled" ;}; };
///{ smp2p-cdsp { status = "disabled" ;}; };

//&qfprom0 { status = "disabled" ;};
//&soc { cpufreq@18323000 { status = "disabled" ;};      };

//&watchdog { status = "disabled" ;};

//&mdss_dsi0 { status = "disabled"; };
//&mdss_dsi0_phy { status = "disabled"; };
//&mdp { status = "disabled"; };
//&mdss { status = "disabled"; };
//&adreno_smmu { status = "disabled"; };
//&gpu { status = "disabled"; };
//&gmu { status = "disabled"; };
//&apps_smmu { status = "disabled"; };
//&panel0 { status = "disabled"; };

/* all related to display-port here */
//&mdss_dp { status = "disabled"; };
//&mdp { ports { /delete-node/ port@2; }; };
//&dp_in { /delete-property/ remote-endpoint; };

/* it stalls 30s for fw loading and prevent gpu fw loading afterward */
//&venus { status = "disabled"; };
//framebuffer { status = "disabled"; };

//&ipa { status = "disabled"; };
//delete-node/ &rmtfs_mem;
//&wifi { status = "disabled"; };

//&usb_1 {status = "disabled";};
//&usb_1_dwc3 {status = "disabled";};
//&usb_1_hsphy {status = "disabled"; };

/* boot blocking obstacle, atoll soc does not handle this addr as clk */
//&soc { clock-controller@63000000       { status = "disabled" ;};      };
//&lpass_hm { status = "disabled" ;}; //same as above

/* looks like below lpass node are not controlled by linux */
//&lpasscc { status = "disabled" ;};
//&lpass_cpu { status = "disabled" ;};
/**************************/

//&soc { clock-controller@62d00000       { status = "disabled" ;};      };
//&soc { clock-controller@af00000        { status = "disabled" ;};      };

//&soc { clock-controller@ad00000        { status = "disabled" ;};      };
//&soc { clock-controller@ab00000        { status = "disabled" ;};      };
//&soc { clock-controller@5090000        { status = "disabled" ;};      };
//&soc { geniqup@ac0000                  { status = "disabled" ;};      };
//&soc { geniqup@8c0000                  { status = "disabled" ;};      };

&pm6150l_labibb { status = "disabled"; };
&pm6150l_wled { status = "disabled"; };

//&ufs_mem_hc { status = "disabled"; };
//&ufs_mem_phy { status = "disabled"; };
